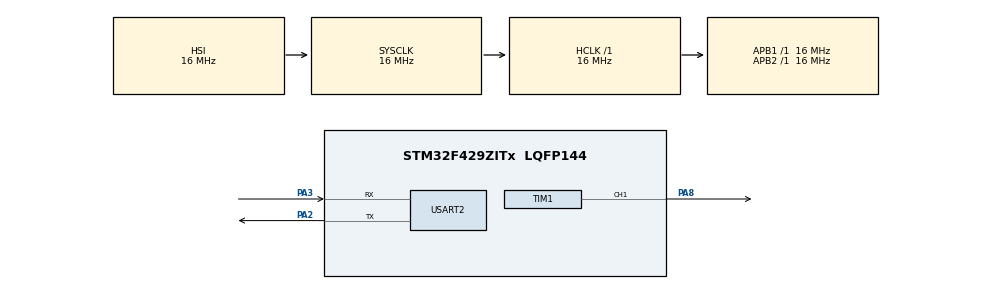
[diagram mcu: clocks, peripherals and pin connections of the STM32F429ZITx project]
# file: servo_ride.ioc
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Mcu.Family=STM32F4
Mcu.Name=STM32F429ZITx
Mcu.Package=LQFP144
NVIC.PriorityGroup=NVIC_PRIORITYGROUP_4
NVIC.USART2_IRQn=true\:0\:0\:false\:false\:true\:true\:true\:true
PA2.Mode=Asynchronous
PA2.Signal=USART2_TX
PA3.Mode=Asynchronous
PA3.Signal=USART2_RX
PA8.Signal=S_TIM1_CH1
ProjectManager.HeapSize=0x200
ProjectManager.StackSize=0x400
ProjectManager.TargetToolchain=STM32CubeIDE
RCC.AHBFreq_Value=16000000
RCC.APB1Freq_Value=16000000
RCC.APB2Freq_Value=16000000
RCC.CortexFreq_Value=16000000
RCC.HSE_VALUE=25000000
RCC.HSI_VALUE=16000000
RCC.LSE_VALUE=32768
RCC.SYSCLKFreq_VALUE=16000000
RCC.VCOOutputFreq_Value=192000000
SH.S_TIM1_CH1.0=TIM1_CH1,PWM Generation1 CH1
TIM1.Channel-PWM\ Generation1\ CH1=TIM_CHANNEL_1
TIM1.Period=20000-1
TIM1.Prescaler=83
USART2.VirtualMode=VM_ASYNC
VP_TIM1_VS_ClockSourceINT.Mode=Internal
board=custom

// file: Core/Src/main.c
/* USER CODE BEGIN Header */
/**
  ******************************************************************************
  * @file           : main.c
  * @brief          : Main program body
  ******************************************************************************
  * @attention
  *
  * Copyright (c) 2024 STMicroelectronics.
  * All rights reserved.
  *
  * This software is licensed under terms that can be found in the LICENSE file
  * in the root directory of this software component.
  * If no LICENSE file comes with this software, it is provided AS-IS.
  *
  ******************************************************************************
  */
/* USER CODE END Header */
#include "main.h"
/* USER CODE BEGIN Includes */
#include "usart.h"
#include "tim.h"
/* USER CODE END Includes */

/* USER CODE BEGIN PD */
#define HEAD 0xf5
#define CMD_SET_ANGLE 0x01
/* USER CODE END PD */

TIM_HandleTypeDef htim1;

UART_HandleTypeDef huart2;

/* USER CODE BEGIN PV */
uint8_t rx_buffer[10];
uint8_t rx_index = 0;
/* USER CODE END PV */

void SystemClock_Config(void);
static void MX_GPIO_Init(void);
static void MX_TIM1_Init(void);
static void MX_USART2_UART_Init(void);

/* USER CODE BEGIN 0 */
void HAL_UART_RxCpltCallback(UART_HandleTypeDef *huart);
/* USER CODE END 0 */

int main(void)
{

  /* MCU Configuration--------------------------------------------------------*/

  /* Reset of all peripherals, Initializes the Flash interface and the Systick. */
  HAL_Init();

  /* Configure the system clock */
  SystemClock_Config();

  /* Initialize all configured peripherals */
  MX_GPIO_Init();
  MX_TIM1_Init();
  MX_USART2_UART_Init();
  /* USER CODE BEGIN 2 */
  HAL_UART_Receive_IT(&huart2, &rx_buffer[rx_index], 1);
  /* USER CODE END 2 */

  /* Infinite loop */
  while (1)
  {

  }
}

void SystemClock_Config(void)
{
  RCC_OscInitTypeDef RCC_OscInitStruct = {0};
  RCC_ClkInitTypeDef RCC_ClkInitStruct = {0};

  /** Configure the main internal regulator output voltage
  */
  __HAL_RCC_PWR_CLK_ENABLE();
  __HAL_PWR_VOLTAGESCALING_CONFIG(PWR_REGULATOR_VOLTAGE_SCALE3);

  /** Initializes the RCC Oscillators according to the specified parameters
  * in the RCC_OscInitTypeDef structure.
  */
  RCC_OscInitStruct.OscillatorType = RCC_OSCILLATORTYPE_HSI;
  RCC_OscInitStruct.HSIState = RCC_HSI_ON;
  RCC_OscInitStruct.HSICalibrationValue = RCC_HSICALIBRATION_DEFAULT;
  RCC_OscInitStruct.PLL.PLLState = RCC_PLL_NONE;
  if (HAL_RCC_OscConfig(&RCC_OscInitStruct) != HAL_OK)
  {
    Error_Handler();
  }

  /** Initializes the CPU, AHB and APB buses clocks
  */
  RCC_ClkInitStruct.ClockType = RCC_CLOCKTYPE_HCLK|RCC_CLOCKTYPE_SYSCLK
                              |RCC_CLOCKTYPE_PCLK1|RCC_CLOCKTYPE_PCLK2;
  RCC_ClkInitStruct.SYSCLKSource = RCC_SYSCLKSOURCE_HSI;
  RCC_ClkInitStruct.AHBCLKDivider = RCC_SYSCLK_DIV1;
  RCC_ClkInitStruct.APB1CLKDivider = RCC_HCLK_DIV1;
  RCC_ClkInitStruct.APB2CLKDivider = RCC_HCLK_DIV1;

  if (HAL_RCC_ClockConfig(&RCC_ClkInitStruct, FLASH_LATENCY_0) != HAL_OK)
  {
    Error_Handler();
  }
}

static void MX_TIM1_Init(void)
{

  TIM_ClockConfigTypeDef sClockSourceConfig = {0};
  TIM_MasterConfigTypeDef sMasterConfig = {0};
  TIM_OC_InitTypeDef sConfigOC = {0};
  TIM_BreakDeadTimeConfigTypeDef sBreakDeadTimeConfig = {0};

  htim1.Instance = TIM1;
  htim1.Init.Prescaler = 83;
  htim1.Init.CounterMode = TIM_COUNTERMODE_UP;
  htim1.Init.Period = 20000-1;
  htim1.Init.ClockDivision = TIM_CLOCKDIVISION_DIV1;
  htim1.Init.RepetitionCounter = 0;
  htim1.Init.AutoReloadPreload = TIM_AUTORELOAD_PRELOAD_DISABLE;
  if (HAL_TIM_Base_Init(&htim1) != HAL_OK)
  {
    Error_Handler();
  }
  sClockSourceConfig.ClockSource = TIM_CLOCKSOURCE_INTERNAL;
  if (HAL_TIM_ConfigClockSource(&htim1, &sClockSourceConfig) != HAL_OK)
  {
    Error_Handler();
  }
  if (HAL_TIM_PWM_Init(&htim1) != HAL_OK)
  {
    Error_Handler();
  }
  sMasterConfig.MasterOutputTrigger = TIM_TRGO_RESET;
  sMasterConfig.MasterSlaveMode = TIM_MASTERSLAVEMODE_DISABLE;
  if (HAL_TIMEx_MasterConfigSynchronization(&htim1, &sMasterConfig) != HAL_OK)
  {
    Error_Handler();
  }
  sConfigOC.OCMode = TIM_OCMODE_PWM1;
  sConfigOC.Pulse = 0;
  sConfigOC.OCPolarity = TIM_OCPOLARITY_HIGH;
  sConfigOC.OCNPolarity = TIM_OCNPOLARITY_HIGH;
  sConfigOC.OCFastMode = TIM_OCFAST_DISABLE;
  sConfigOC.OCIdleState = TIM_OCIDLESTATE_RESET;
  sConfigOC.OCNIdleState = TIM_OCNIDLESTATE_RESET;
  if (HAL_TIM_PWM_ConfigChannel(&htim1, &sConfigOC, TIM_CHANNEL_1) != HAL_OK)
  {
    Error_Handler();
  }
  sBreakDeadTimeConfig.OffStateRunMode = TIM_OSSR_DISABLE;
  sBreakDeadTimeConfig.OffStateIDLEMode = TIM_OSSI_DISABLE;
  sBreakDeadTimeConfig.LockLevel = TIM_LOCKLEVEL_OFF;
  sBreakDeadTimeConfig.DeadTime = 0;
  sBreakDeadTimeConfig.BreakState = TIM_BREAK_DISABLE;
  sBreakDeadTimeConfig.BreakPolarity = TIM_BREAKPOLARITY_HIGH;
  sBreakDeadTimeConfig.AutomaticOutput = TIM_AUTOMATICOUTPUT_DISABLE;
  if (HAL_TIMEx_ConfigBreakDeadTime(&htim1, &sBreakDeadTimeConfig) != HAL_OK)
  {
    Error_Handler();
  }
  HAL_TIM_MspPostInit(&htim1);

}

static void MX_USART2_UART_Init(void)
{

  huart2.Instance = USART2;
  huart2.Init.BaudRate = 115200;
  huart2.Init.WordLength = UART_WORDLENGTH_8B;
  huart2.Init.StopBits = UART_STOPBITS_1;
  huart2.Init.Parity = UART_PARITY_NONE;
  huart2.Init.Mode = UART_MODE_TX_RX;
  huart2.Init.HwFlowCtl = UART_HWCONTROL_NONE;
  huart2.Init.OverSampling = UART_OVERSAMPLING_16;
  if (HAL_UART_Init(&huart2) != HAL_OK)
  {
    Error_Handler();
  }

}

static void MX_GPIO_Init(void)
{

  /* GPIO Ports Clock Enable */
  __HAL_RCC_GPIOA_CLK_ENABLE();

}

/* USER CODE BEGIN 4 */

void HAL_UART_RxCpltCallback(UART_HandleTypeDef *huart) {
    if (huart->Instance == USART2) {
        uint8_t received = rx_buffer[rx_index];
        if (rx_index == 0 && received != HEAD) {
            rx_index = 0;
        } else {
            rx_index++;
            if (rx_index == 2) {
                uint8_t length = rx_buffer[1];
                if (length > 10) {
                    rx_index = 0;
                }
            } else if (rx_index == rx_buffer[1] + 1) {
                if (rx_buffer[2] == CMD_SET_ANGLE) {
                    uint8_t id = rx_buffer[3];
                    uint8_t angle = rx_buffer[4];
                    uint8_t speed = rx_buffer[5];
                    set_servo_angle(id, angle, speed);
                }
                rx_index = 0;
            }
        }
        HAL_UART_Receive_IT(&huart2, &rx_buffer[rx_index], 1);
    }
}

void set_servo_angle(uint8_t id, uint8_t angle, uint8_t speed) {
    uint16_t pulse_length = (uint16_t)((1000 + (angle * 1000 / 180)) * (SystemCoreClock / 1000000) - 1);
    __HAL_TIM_SET_COMPARE(&htim1, TIM_CHANNEL_1, pulse_length);
    HAL_TIM_PWM_Start(&htim1, TIM_CHANNEL_1);
}
/* USER CODE END 4 */

void Error_Handler(void)
{
  __disable_irq();
  while (1)
  {
  }
}
